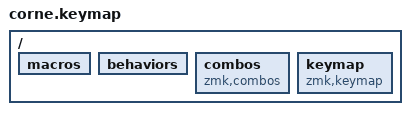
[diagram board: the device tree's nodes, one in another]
/*
 * Copyright (c) 2020 The ZMK Contributors
 *
 * SPDX-License-Identifier: MIT
 */

#include <behaviors.dtsi>
#include <dt-bindings/zmk/keys.h>
#include <dt-bindings/zmk/bt.h>

/* Global */
#include "os/shared/times.dtsi"
#include "os/shared/general.dtsi"
#include "os/macos/layers.dtsi"

/* Keys */
#include "os/shared/keys.dtsi"
#include "os/macos/keys.dtsi"

/* Helpers */
#include "helpers/macros.dtsi"
#include "helpers/hold.dtsi"
#include "helpers/morph.dtsi"

/ {
    macros {
        #include "os/shared/macros/layers.dtsi"
        #include "os/shared/macros/settings.dtsi"

        #include "os/macos/macros/layers.dtsi"
        #include "os/macos/macros/int.dtsi"
        #include "os/macos/macros/dev.dtsi"
    };
};

/ {
    behaviors {
        #include "os/shared/morph/shared.dtsi"
        #include "os/shared/morph/num.dtsi"
        #include "os/shared/hold/shared.dtsi"

        #include "os/macos/morph/layers.dtsi"
        #include "os/macos/morph/base.dtsi"
        #include "os/macos/morph/int.dtsi"
        #include "os/macos/morph/actions.dtsi"
        #include "os/macos/morph/dev.dtsi"
        #include "os/macos/morph/settings.dtsi"
        #include "os/macos/hold/layers.dtsi"
        #include "os/macos/hold/base.dtsi"
        #include "os/macos/hold/dev.dtsi"
        #include "os/macos/hold/settings.dtsi"
    };
};

/ {
    combos {
        compatible = "zmk,combos";

        #include "os/macos/combos/base.dtsi"
        #include "os/macos/combos/help.dtsi"
    };
};

/ {
    keymap {
        compatible = "zmk,keymap";

        #include "os/macos/keymap.dtsi"
    };
};
